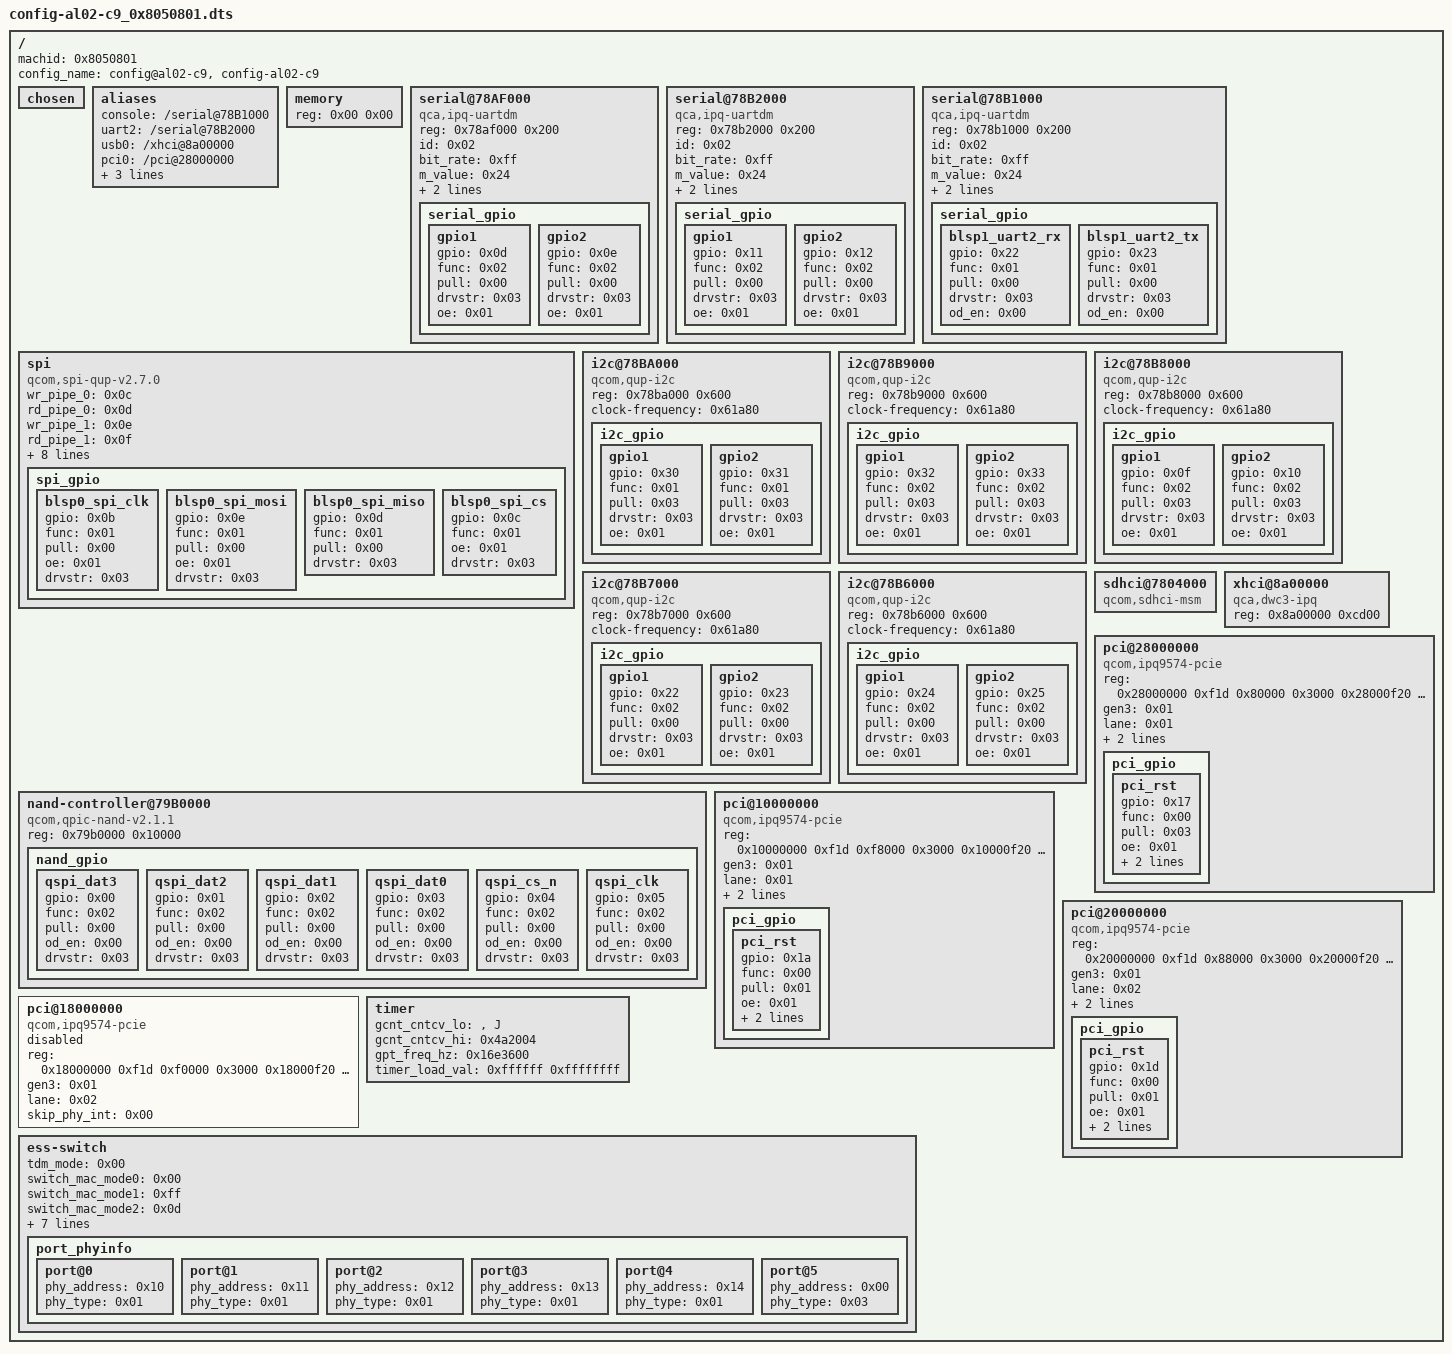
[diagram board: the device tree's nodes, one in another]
/dts-v1/;

/ {
	#address-cells = <0x01>;
	#size-cells = <0x01>;
	machid = <0x8050801>;
	config_name = "config@al02-c9", "config-al02-c9";

	chosen {
	};

	aliases {
		console = "/serial@78B1000";
		uart2 = "/serial@78B2000";
		usb0 = "/xhci@8a00000";
		pci0 = "/pci@28000000";
		nand = "/nand-controller@79B0000";
		i2c0 = "/i2c@78B8000";
		pci2 = "/pci@20000000";
	};

	memory {
		device_type = "memory";
		reg = <0x00 0x00>;
	};

	serial@78AF000 {
		compatible = "qca,ipq-uartdm";
		reg = <0x78af000 0x200>;
		id = <0x02>;
		bit_rate = <0xff>;
		status = "ok";
		m_value = <0x24>;
		n_value = <0x3d09>;
		d_value = <0x3d09>;

		serial_gpio {

			gpio1 {
				gpio = <0x0d>;
				func = <0x02>;
				pull = <0x00>;
				drvstr = <0x03>;
				oe = <0x01>;
			};

			gpio2 {
				gpio = <0x0e>;
				func = <0x02>;
				pull = <0x00>;
				drvstr = <0x03>;
				oe = <0x01>;
			};
		};
	};

	serial@78B2000 {
		compatible = "qca,ipq-uartdm";
		reg = <0x78b2000 0x200>;
		id = <0x02>;
		bit_rate = <0xff>;
		status = "ok";
		m_value = <0x24>;
		n_value = <0x3d09>;
		d_value = <0x3d09>;

		serial_gpio {

			gpio1 {
				gpio = <0x11>;
				func = <0x02>;
				pull = <0x00>;
				drvstr = <0x03>;
				oe = <0x01>;
			};

			gpio2 {
				gpio = <0x12>;
				func = <0x02>;
				pull = <0x00>;
				drvstr = <0x03>;
				oe = <0x01>;
			};
		};
	};

	serial@78B1000 {
		compatible = "qca,ipq-uartdm";
		reg = <0x78b1000 0x200>;
		id = <0x02>;
		bit_rate = <0xff>;
		status = "ok";
		m_value = <0x24>;
		n_value = <0x3d09>;
		d_value = <0x3d09>;

		serial_gpio {

			blsp1_uart2_rx {
				gpio = <0x22>;
				func = <0x01>;
				pull = <0x00>;
				drvstr = <0x03>;
				od_en = <0x00>;
			};

			blsp1_uart2_tx {
				gpio = <0x23>;
				func = <0x01>;
				pull = <0x00>;
				drvstr = <0x03>;
				od_en = <0x00>;
			};
		};
	};

	spi {
		compatible = "qcom,spi-qup-v2.7.0";
		wr_pipe_0 = <0x0c>;
		rd_pipe_0 = <0x0d>;
		wr_pipe_1 = <0x0e>;
		rd_pipe_1 = <0x0f>;
		wr_pipe_2 = <0x10>;
		rd_pipe_2 = <0x11>;
		wr_pipe_3 = <0x12>;
		rd_pipe_3 = <0x13>;
		wr_pipe_4 = <0x14>;
		rd_pipe_4 = <0x15>;
		wr_pipe_5 = <0x16>;
		rd_pipe_5 = <0x17>;
		status = "ok";

		spi_gpio {

			blsp0_spi_clk {
				gpio = <0x0b>;
				func = <0x01>;
				pull = <0x00>;
				oe = <0x01>;
				drvstr = <0x03>;
			};

			blsp0_spi_mosi {
				gpio = <0x0e>;
				func = <0x01>;
				pull = <0x00>;
				oe = <0x01>;
				drvstr = <0x03>;
			};

			blsp0_spi_miso {
				gpio = <0x0d>;
				func = <0x01>;
				pull = <0x00>;
				drvstr = <0x03>;
			};

			blsp0_spi_cs {
				gpio = <0x0c>;
				func = <0x01>;
				oe = <0x01>;
				drvstr = <0x03>;
			};
		};
	};

	i2c@78BA000 {
		compatible = "qcom,qup-i2c";
		#address-cells = <0x01>;
		#size-cells = <0x00>;
		reg = <0x78ba000 0x600>;
		clock-frequency = <0x61a80>;

		i2c_gpio {

			gpio1 {
				gpio = <0x30>;
				func = <0x01>;
				pull = <0x03>;
				drvstr = <0x03>;
				oe = <0x01>;
			};

			gpio2 {
				gpio = <0x31>;
				func = <0x01>;
				pull = <0x03>;
				drvstr = <0x03>;
				oe = <0x01>;
			};
		};
	};

	i2c@78B9000 {
		compatible = "qcom,qup-i2c";
		#address-cells = <0x01>;
		#size-cells = <0x00>;
		reg = <0x78b9000 0x600>;
		clock-frequency = <0x61a80>;

		i2c_gpio {

			gpio1 {
				gpio = <0x32>;
				func = <0x02>;
				pull = <0x03>;
				drvstr = <0x03>;
				oe = <0x01>;
			};

			gpio2 {
				gpio = <0x33>;
				func = <0x02>;
				pull = <0x03>;
				drvstr = <0x03>;
				oe = <0x01>;
			};
		};
	};

	i2c@78B8000 {
		compatible = "qcom,qup-i2c";
		#address-cells = <0x01>;
		#size-cells = <0x00>;
		reg = <0x78b8000 0x600>;
		clock-frequency = <0x61a80>;

		i2c_gpio {

			gpio1 {
				gpio = <0x0f>;
				func = <0x02>;
				pull = <0x03>;
				drvstr = <0x03>;
				oe = <0x01>;
			};

			gpio2 {
				gpio = <0x10>;
				func = <0x02>;
				pull = <0x03>;
				drvstr = <0x03>;
				oe = <0x01>;
			};
		};
	};

	i2c@78B7000 {
		compatible = "qcom,qup-i2c";
		#address-cells = <0x01>;
		#size-cells = <0x00>;
		reg = <0x78b7000 0x600>;
		clock-frequency = <0x61a80>;

		i2c_gpio {

			gpio1 {
				gpio = <0x22>;
				func = <0x02>;
				pull = <0x00>;
				drvstr = <0x03>;
				oe = <0x01>;
			};

			gpio2 {
				gpio = <0x23>;
				func = <0x02>;
				pull = <0x00>;
				drvstr = <0x03>;
				oe = <0x01>;
			};
		};
	};

	i2c@78B6000 {
		compatible = "qcom,qup-i2c";
		#address-cells = <0x01>;
		#size-cells = <0x00>;
		reg = <0x78b6000 0x600>;
		clock-frequency = <0x61a80>;

		i2c_gpio {

			gpio1 {
				gpio = <0x24>;
				func = <0x02>;
				pull = <0x00>;
				drvstr = <0x03>;
				oe = <0x01>;
			};

			gpio2 {
				gpio = <0x25>;
				func = <0x02>;
				pull = <0x00>;
				drvstr = <0x03>;
				oe = <0x01>;
			};
		};
	};

	nand-controller@79B0000 {
		#address-cells = <0x01>;
		#size-cells = <0x00>;
		compatible = "qcom,qpic-nand-v2.1.1";
		reg = <0x79b0000 0x10000>;
		status = "okay";

		nand_gpio {

			qspi_dat3 {
				gpio = <0x00>;
				func = <0x02>;
				pull = <0x00>;
				od_en = <0x00>;
				drvstr = <0x03>;
			};

			qspi_dat2 {
				gpio = <0x01>;
				func = <0x02>;
				pull = <0x00>;
				od_en = <0x00>;
				drvstr = <0x03>;
			};

			qspi_dat1 {
				gpio = <0x02>;
				func = <0x02>;
				pull = <0x00>;
				od_en = <0x00>;
				drvstr = <0x03>;
			};

			qspi_dat0 {
				gpio = <0x03>;
				func = <0x02>;
				pull = <0x00>;
				od_en = <0x00>;
				drvstr = <0x03>;
			};

			qspi_cs_n {
				gpio = <0x04>;
				func = <0x02>;
				pull = <0x00>;
				od_en = <0x00>;
				drvstr = <0x03>;
			};

			qspi_clk {
				gpio = <0x05>;
				func = <0x02>;
				pull = <0x00>;
				od_en = <0x00>;
				drvstr = <0x03>;
			};
		};
	};

	sdhci@7804000 {
		compatible = "qcom,sdhci-msm";
	};

	xhci@8a00000 {
		compatible = "qca,dwc3-ipq";
		#address-cells = <0x01>;
		#size-cells = <0x01>;
		reg = <0x8a00000 0xcd00>;
	};

	pci@28000000 {
		compatible = "qcom,ipq9574-pcie";
		#address-cells = <0x01>;
		#size-cells = <0x01>;
		reg = <0x28000000 0xf1d 0x80000 0x3000 0x28000f20 0xa8 0x28001000 0x1000 0x28300000 0xd00000 0x28100000 0x100000 0x1828000 0x60 0x84000 0x1000>;
		reg-names = "pci_dbi", "parf", "elbi", "dm_iatu", "axi_bars", "axi_conf", "pci_rst", "pci_phy";
		gen3 = <0x01>;
		lane = <0x01>;
		status = "ok";
		skip_phy_int = <0x00>;
		perst_gpio = <0x17>;

		pci_gpio {

			pci_rst {
				gpio = <0x17>;
				func = <0x00>;
				pull = <0x03>;
				oe = <0x01>;
				od_en = <0x00>;
				drvstr = <0x03>;
			};
		};
	};

	pci@10000000 {
		compatible = "qcom,ipq9574-pcie";
		#address-cells = <0x01>;
		#size-cells = <0x01>;
		reg = <0x10000000 0xf1d 0xf8000 0x3000 0x10000f20 0xa8 0x10001000 0x1000 0x10300000 0xd00000 0x10100000 0x100000 0x182b000 0x60 0xfc000 0x1000>;
		reg-names = "pci_dbi", "parf", "elbi", "dm_iatu", "axi_bars", "axi_conf", "pci_rst", "pci_phy";
		gen3 = <0x01>;
		lane = <0x01>;
		status = "ok";
		skip_phy_int = <0x00>;
		perst_gpio = <0x1a>;

		pci_gpio {

			pci_rst {
				gpio = <0x1a>;
				func = <0x00>;
				pull = <0x01>;
				oe = <0x01>;
				od_en = <0x00>;
				drvstr = <0x03>;
			};
		};
	};

	pci@20000000 {
		compatible = "qcom,ipq9574-pcie";
		#address-cells = <0x01>;
		#size-cells = <0x01>;
		reg = <0x20000000 0xf1d 0x88000 0x3000 0x20000f20 0xa8 0x20001000 0x1000 0x20300000 0xd00000 0x20100000 0x100000 0x1829000 0x60 0x8c000 0x1000>;
		reg-names = "pci_dbi", "parf", "elbi", "dm_iatu", "axi_bars", "axi_conf", "pci_rst", "pci_phy";
		gen3 = <0x01>;
		lane = <0x02>;
		status = "ok";
		skip_phy_int = <0x00>;
		perst_gpio = <0x1d>;

		pci_gpio {

			pci_rst {
				gpio = <0x1d>;
				func = <0x00>;
				pull = <0x01>;
				oe = <0x01>;
				od_en = <0x00>;
				drvstr = <0x03>;
			};
		};
	};

	pci@18000000 {
		compatible = "qcom,ipq9574-pcie";
		#address-cells = <0x01>;
		#size-cells = <0x01>;
		reg = <0x18000000 0xf1d 0xf0000 0x3000 0x18000f20 0xa8 0x18001000 0x1000 0x18300000 0xd00000 0x18100000 0x100000 0x182a000 0x60 0xf4000 0x1000>;
		reg-names = "pci_dbi", "parf", "elbi", "dm_iatu", "axi_bars", "axi_conf", "pci_rst", "pci_phy";
		gen3 = <0x01>;
		lane = <0x02>;
		status = "disabled";
		skip_phy_int = <0x00>;
	};

	timer {
		gcnt_cntcv_lo = "", "J ";
		gcnt_cntcv_hi = <0x4a2004>;
		gpt_freq_hz = <0x16e3600>;
		timer_load_val = <0xffffff 0xffffffff>;
	};

	ess-switch {
		tdm_mode = <0x00>;
		switch_mac_mode0 = <0x00>;
		switch_mac_mode1 = <0xff>;
		switch_mac_mode2 = <0x0d>;
		qca807x_gpio = <0x3c>;
		qca807x_gpio_cnt = <0x01>;
		aquantia_gpio = <0x24>;
		aquantia_gpio_cnt = <0x01>;
		aquantia_port = <0x05>;
		aquantia_port_cnt = <0x01>;
		mdc_mdio_gpio = <0x26 0x27>;

		port_phyinfo {

			port@0 {
				phy_address = <0x10>;
				phy_type = <0x01>;
			};

			port@1 {
				phy_address = <0x11>;
				phy_type = <0x01>;
			};

			port@2 {
				phy_address = <0x12>;
				phy_type = <0x01>;
			};

			port@3 {
				phy_address = <0x13>;
				phy_type = <0x01>;
			};

			port@4 {
				phy_address = <0x14>;
				phy_type = <0x01>;
			};

			port@5 {
				phy_address = <0x00>;
				phy_type = <0x03>;
			};
		};
	};
};
